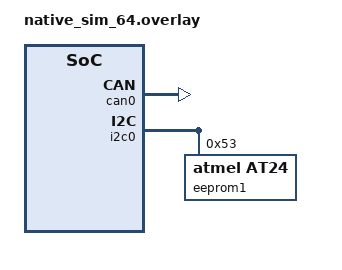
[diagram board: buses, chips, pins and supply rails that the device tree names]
/ {
	chosen {
		zephyr,canbus = &can0;
	};
};

&can0 {
	status = "okay";
	host-interface = "vcan0";
};

&i2c0 {
	status = "okay";
	eeprom1: eeprom@53 {
		status = "okay";
		compatible = "atmel,at24";
		reg=<0x53>;
		size = <DT_SIZE_K(64)>;
		timeout = <5>;
		pagesize = <16>;
		address-width = <16>;
	};
};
